VERSION ""

NS_ :

BS_:

BU_: VehicleECU AgentECU

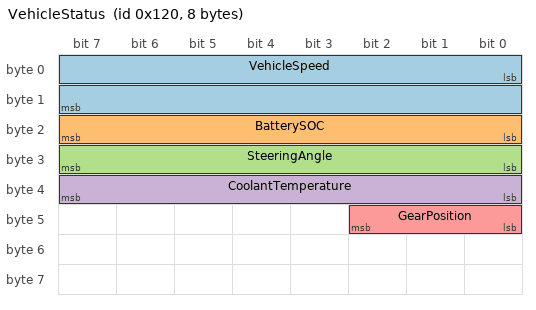
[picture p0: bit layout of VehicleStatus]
BO_ 288 VehicleStatus: 8 VehicleECU
 SG_ VehicleSpeed : 0|16@1+ (0.01,0) [0|250] "km/h" AgentECU
 SG_ BatterySOC : 16|8@1+ (1,0) [0|100] "%" AgentECU
 SG_ SteeringAngle : 24|8@1- (0.5,0) [-64|63.5] "deg" AgentECU
 SG_ CoolantTemperature : 32|8@1+ (1,-40) [-40|215] "degC" AgentECU
 SG_ GearPosition : 40|3@1+ (1,0) [0|7] "" AgentECU
